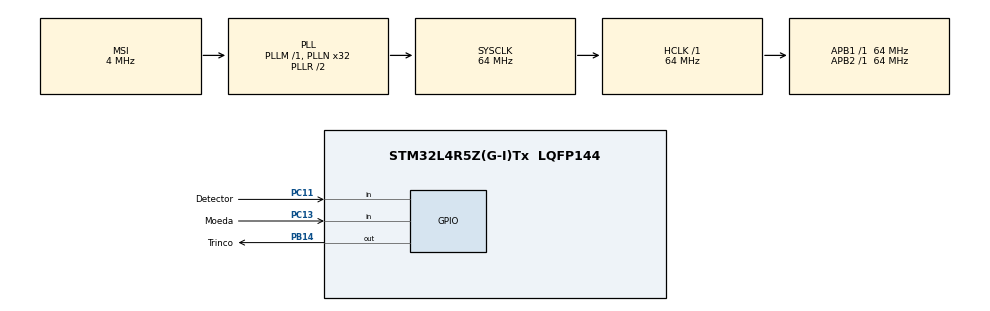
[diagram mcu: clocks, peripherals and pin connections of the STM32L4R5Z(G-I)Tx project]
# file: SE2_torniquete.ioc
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Mcu.Family=STM32L4
Mcu.Name=STM32L4R5Z(G-I)Tx
Mcu.Package=LQFP144
NVIC.PriorityGroup=NVIC_PRIORITYGROUP_4
PA13\ (JTMS/SWDIO).Mode=Trace_Asynchronous_SW
PA13\ (JTMS/SWDIO).Signal=SYS_JTMS-SWDIO
PA14\ (JTCK/SWCLK).Mode=Trace_Asynchronous_SW
PA14\ (JTCK/SWCLK).Signal=SYS_JTCK-SWCLK
PB14.GPIO_Label=Trinco
PB14.GPIO_PuPd=GPIO_NOPULL
PB14.Signal=GPIO_Output
PB3\ (JTDO/TRACESWO).Mode=Trace_Asynchronous_SW
PB3\ (JTDO/TRACESWO).Signal=SYS_JTDO-SWO
PC11.GPIO_Label=Detector
PC11.GPIO_PuPd=GPIO_PULLDOWN
PC11.Signal=GPIO_Input
PC13.GPIO_Label=Moeda
PC13.Signal=GPIO_Input
ProjectManager.HeapSize=0x200
ProjectManager.StackSize=0x400
ProjectManager.TargetToolchain=STM32CubeIDE
RCC.AHBFreq_Value=64000000
RCC.APB1Freq_Value=64000000
RCC.APB1TimFreq_Value=64000000
RCC.APB2Freq_Value=64000000
RCC.APB2TimFreq_Value=64000000
RCC.CortexFreq_Value=64000000
RCC.HCLKFreq_Value=64000000
RCC.HSE_VALUE=8000000
RCC.HSI48_VALUE=48000000
RCC.HSI_VALUE=16000000
RCC.LSE_VALUE=32768
RCC.MSI_VALUE=4000000
RCC.PLLN=32
RCC.SYSCLKFreq_VALUE=64000000
RCC.SYSCLKSource=RCC_SYSCLKSOURCE_PLLCLK
RCC.VCOOutputFreq_Value=128000000
board=custom

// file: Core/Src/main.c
/* USER CODE BEGIN Header */
/**
  ******************************************************************************
  * @file           : main.c
  * @brief          : Main program body
  ******************************************************************************
  * @attention
  *
  * Copyright (c) 2023 STMicroelectronics.
  * All rights reserved.
  *
  * This software is licensed under terms that can be found in the LICENSE file
  * in the root directory of this software component.
  * If no LICENSE file comes with this software, it is provided AS-IS.
  *
  ******************************************************************************
  */
/* USER CODE END Header */
#include "main.h"

/* USER CODE BEGIN PTD */
typedef enum{
	LOCKED,
	UNLOCKED,
}states_t;
/* USER CODE END PTD */

/* USER CODE BEGIN PV */

states_t state=LOCKED;
GPIO_PinState lastDetector = GPIO_PIN_SET, currDetector;

/* USER CODE END PV */

void SystemClock_Config(void);
static void MX_GPIO_Init(void);

int main(void)
{

  /* MCU Configuration--------------------------------------------------------*/

  /* Reset of all peripherals, Initializes the Flash interface and the Systick. */
  HAL_Init();

  /* Configure the system clock */
  SystemClock_Config();

  /* Initialize all configured peripherals */
  MX_GPIO_Init();

  /* Infinite loop */
  /* USER CODE BEGIN WHILE */
  while (1)
  {
	  switch(state){
	  	  case LOCKED:
	  		  HAL_GPIO_WritePin(Trinco_GPIO_Port, Trinco_Pin, GPIO_PIN_RESET);
	  		  if(HAL_GPIO_ReadPin(Moeda_GPIO_Port, Moeda_Pin)){
	  			  state= UNLOCKED;
	  		  }
	  		  break;
	  	  case UNLOCKED:
	  		  HAL_GPIO_WritePin(Trinco_GPIO_Port, Trinco_Pin, GPIO_PIN_SET);
	  		  currDetector = HAL_GPIO_ReadPin(Detector_GPIO_Port, Detector_Pin);
	  		  if(!lastDetector && currDetector){
	  			  state = LOCKED;
	  		  }
	  		  lastDetector = currDetector;
	  		  break;
	  	  default: state = LOCKED;
	  }

    /* USER CODE END WHILE */

  }
}

void SystemClock_Config(void)
{
  RCC_OscInitTypeDef RCC_OscInitStruct = {0};
  RCC_ClkInitTypeDef RCC_ClkInitStruct = {0};

  /** Configure the main internal regulator output voltage
  */
  if (HAL_PWREx_ControlVoltageScaling(PWR_REGULATOR_VOLTAGE_SCALE1) != HAL_OK)
  {
    Error_Handler();
  }

  /** Initializes the RCC Oscillators according to the specified parameters
  * in the RCC_OscInitTypeDef structure.
  */
  RCC_OscInitStruct.OscillatorType = RCC_OSCILLATORTYPE_MSI;
  RCC_OscInitStruct.MSIState = RCC_MSI_ON;
  RCC_OscInitStruct.MSICalibrationValue = 0;
  RCC_OscInitStruct.MSIClockRange = RCC_MSIRANGE_6;
  RCC_OscInitStruct.PLL.PLLState = RCC_PLL_ON;
  RCC_OscInitStruct.PLL.PLLSource = RCC_PLLSOURCE_MSI;
  RCC_OscInitStruct.PLL.PLLM = 1;
  RCC_OscInitStruct.PLL.PLLN = 32;
  RCC_OscInitStruct.PLL.PLLP = RCC_PLLP_DIV2;
  RCC_OscInitStruct.PLL.PLLQ = RCC_PLLQ_DIV2;
  RCC_OscInitStruct.PLL.PLLR = RCC_PLLR_DIV2;
  if (HAL_RCC_OscConfig(&RCC_OscInitStruct) != HAL_OK)
  {
    Error_Handler();
  }

  /** Initializes the CPU, AHB and APB buses clocks
  */
  RCC_ClkInitStruct.ClockType = RCC_CLOCKTYPE_HCLK|RCC_CLOCKTYPE_SYSCLK
                              |RCC_CLOCKTYPE_PCLK1|RCC_CLOCKTYPE_PCLK2;
  RCC_ClkInitStruct.SYSCLKSource = RCC_SYSCLKSOURCE_PLLCLK;
  RCC_ClkInitStruct.AHBCLKDivider = RCC_SYSCLK_DIV1;
  RCC_ClkInitStruct.APB1CLKDivider = RCC_HCLK_DIV1;
  RCC_ClkInitStruct.APB2CLKDivider = RCC_HCLK_DIV1;

  if (HAL_RCC_ClockConfig(&RCC_ClkInitStruct, FLASH_LATENCY_3) != HAL_OK)
  {
    Error_Handler();
  }
}

static void MX_GPIO_Init(void)
{
  GPIO_InitTypeDef GPIO_InitStruct = {0};

  /* GPIO Ports Clock Enable */
  __HAL_RCC_GPIOC_CLK_ENABLE();
  __HAL_RCC_GPIOB_CLK_ENABLE();
  __HAL_RCC_GPIOA_CLK_ENABLE();

  /*Configure GPIO pin Output Level */
  HAL_GPIO_WritePin(Trinco_GPIO_Port, Trinco_Pin, GPIO_PIN_RESET);

  /*Configure GPIO pin : Moeda_Pin */
  GPIO_InitStruct.Pin = Moeda_Pin;
  GPIO_InitStruct.Mode = GPIO_MODE_INPUT;
  GPIO_InitStruct.Pull = GPIO_NOPULL;
  HAL_GPIO_Init(Moeda_GPIO_Port, &GPIO_InitStruct);

  /*Configure GPIO pin : Trinco_Pin */
  GPIO_InitStruct.Pin = Trinco_Pin;
  GPIO_InitStruct.Mode = GPIO_MODE_OUTPUT_PP;
  GPIO_InitStruct.Pull = GPIO_NOPULL;
  GPIO_InitStruct.Speed = GPIO_SPEED_FREQ_LOW;
  HAL_GPIO_Init(Trinco_GPIO_Port, &GPIO_InitStruct);

  /*Configure GPIO pin : Detector_Pin */
  GPIO_InitStruct.Pin = Detector_Pin;
  GPIO_InitStruct.Mode = GPIO_MODE_INPUT;
  GPIO_InitStruct.Pull = GPIO_PULLDOWN;
  HAL_GPIO_Init(Detector_GPIO_Port, &GPIO_InitStruct);

}

void Error_Handler(void)
{
  __disable_irq();
  while (1)
  {
  }
}
